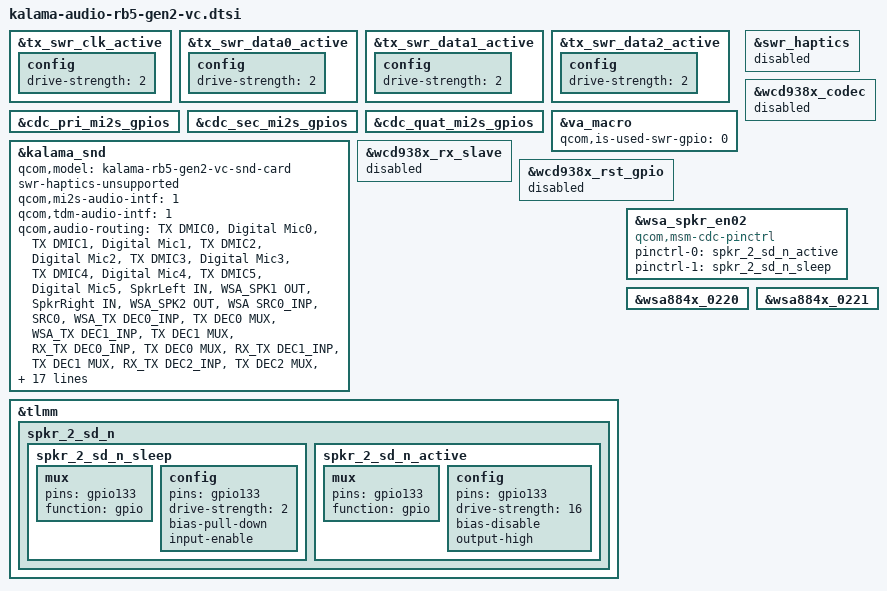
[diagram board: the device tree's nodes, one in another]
#include "kalama-audio-rb5-gen2-overlay.dtsi"
&tx_swr_clk_active {
	config {
		drive-strength = <2>;
	};
};

&tx_swr_data0_active {
	config {
		drive-strength = <2>;
	};
};

&tx_swr_data1_active {
	config {
		drive-strength = <2>;
	};
};

&tx_swr_data2_active {
	config {
		drive-strength = <2>;
	};
};

&cdc_pri_mi2s_gpios {
	status = "ok";
};

&cdc_sec_mi2s_gpios {
	status = "ok";
};

&cdc_quat_mi2s_gpios {
	status = "ok";
};

&va_macro {
	/delete-property/ qcom,va-swr-gpios;
	qcom,is-used-swr-gpio = <0>;
};

&kalama_snd {
	qcom,model = "kalama-rb5-gen2-vc-snd-card";
	swr-haptics-unsupported;
	qcom,mi2s-audio-intf = <1>;
	qcom,tdm-audio-intf = <1>;
	qcom,audio-routing =
		"TX DMIC0", "Digital Mic0",
		"TX DMIC1", "Digital Mic1",
		"TX DMIC2", "Digital Mic2",
		"TX DMIC3", "Digital Mic3",
		"TX DMIC4", "Digital Mic4",
		"TX DMIC5", "Digital Mic5",
		"SpkrLeft IN", "WSA_SPK1 OUT",
		"SpkrRight IN", "WSA_SPK2 OUT",
		"WSA SRC0_INP", "SRC0",
		"WSA_TX DEC0_INP", "TX DEC0 MUX",
		"WSA_TX DEC1_INP", "TX DEC1 MUX",
		"RX_TX DEC0_INP", "TX DEC0 MUX",
		"RX_TX DEC1_INP", "TX DEC1 MUX",
		"RX_TX DEC2_INP", "TX DEC2 MUX",
		"RX_TX DEC3_INP", "TX DEC3 MUX",
		"VA SWR_INPUT", "VA_SWR_CLK",
		"VA_AIF1 CAP", "VA_SWR_CLK",
		"VA_AIF2 CAP", "VA_SWR_CLK",
		"VA_AIF3 CAP", "VA_SWR_CLK",
		"VA DMIC0", "Digital Mic0",
		"VA DMIC1", "Digital Mic1",
		"VA DMIC2", "Digital Mic2",
		"VA DMIC3", "Digital Mic3",
		"VA DMIC4", "Digital Mic4",
		"VA DMIC5", "Digital Mic5";

		asoc-codec = <&stub_codec>, <&lpass_cdc>,
			<&wsa884x_0220>, <&wsa884x_0221>;
		asoc-codec-names = "msm-stub-codec.1", "lpass-cdc",
			"wsa-codec1", "wsa-codec2";
		qcom,wsa-max-devs = <2>;
		qcom,wcd-disabled = <1>;
		qcom,pri-mi2s-gpios = <&cdc_pri_mi2s_gpios>;
		qcom,sec-mi2s-gpios = <&cdc_sec_mi2s_gpios>;
		qcom,quat-mi2s-gpios = <&cdc_quat_mi2s_gpios>;
};

&swr_haptics {
	status = "disabled";
};

&wcd938x_rx_slave {
	status = "disabled";
};

&wcd938x_codec {
	status = "disabled";
};

&wcd938x_rst_gpio {
	status = "disabled";
};

&tlmm {
	spkr_2_sd_n {
		spkr_2_sd_n_sleep: spkr_2_sd_n_sleep {
			mux {
				pins = "gpio133";
				function = "gpio";
			};

			config {
				pins = "gpio133";
				drive-strength = <2>;   /* 2 mA */
				bias-pull-down;
				input-enable;
			};
		};

		spkr_2_sd_n_active: spkr_2_sd_n_active {
			mux {
				pins = "gpio133";
				function = "gpio";
			};

			config {
				pins = "gpio133";
				drive-strength = <16>;   /* 16 mA */
				bias-disable;
				output-high;
			};
		};
	};
};

&wsa_spkr_en02 {
	compatible = "qcom,msm-cdc-pinctrl";
	pinctrl-names = "aud_active", "aud_sleep";
	pinctrl-0 = <&spkr_2_sd_n_active>;
	pinctrl-1 = <&spkr_2_sd_n_sleep>;
};

&wsa884x_0220 {
	status = "okay";
};

&wsa884x_0221 {
	status = "okay";
};
